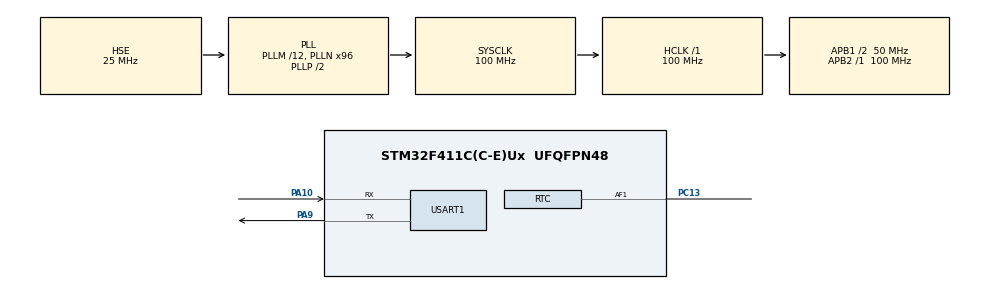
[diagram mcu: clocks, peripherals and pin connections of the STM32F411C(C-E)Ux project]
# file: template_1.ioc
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Dma.Request0=USART1_RX
Dma.Request1=USART1_TX
Dma.USART1_RX.0.Direction=DMA_PERIPH_TO_MEMORY
Dma.USART1_RX.0.FIFOMode=DMA_FIFOMODE_DISABLE
Dma.USART1_RX.0.Instance=DMA2_Stream2
Dma.USART1_RX.0.MemDataAlignment=DMA_MDATAALIGN_BYTE
Dma.USART1_RX.0.MemInc=DMA_MINC_ENABLE
Dma.USART1_RX.0.Mode=DMA_CIRCULAR
Dma.USART1_RX.0.PeriphDataAlignment=DMA_PDATAALIGN_BYTE
Dma.USART1_RX.0.PeriphInc=DMA_PINC_DISABLE
Dma.USART1_RX.0.Priority=DMA_PRIORITY_MEDIUM
Dma.USART1_TX.1.Direction=DMA_MEMORY_TO_PERIPH
Dma.USART1_TX.1.FIFOMode=DMA_FIFOMODE_DISABLE
Dma.USART1_TX.1.Instance=DMA2_Stream7
Dma.USART1_TX.1.MemDataAlignment=DMA_MDATAALIGN_BYTE
Dma.USART1_TX.1.MemInc=DMA_MINC_ENABLE
Dma.USART1_TX.1.Mode=DMA_CIRCULAR
Dma.USART1_TX.1.PeriphDataAlignment=DMA_PDATAALIGN_BYTE
Dma.USART1_TX.1.PeriphInc=DMA_PINC_DISABLE
Dma.USART1_TX.1.Priority=DMA_PRIORITY_MEDIUM
FREERTOS.Queues01=m_input_to_log,1,uint32_t,0,Dynamic,NULL,NULL;m_log_to_output,1,uint32_t,0,Dynamic,NULL,NULL;m_output_to_input,1,uint32_t,0,Dynamic,NULL,NULL
FREERTOS.Tasks01=t_input,32,128,start_t_input,Default,NULL,Dynamic,NULL,NULL;t_log,24,128,start_t_log,Default,NULL,Dynamic,NULL,NULL;t_output,24,128,start_t_output,Default,NULL,Dynamic,NULL,NULL
Mcu.Family=STM32F4
Mcu.Name=STM32F411C(C-E)Ux
Mcu.Package=UFQFPN48
NVIC.DMA2_Stream2_IRQn=true\:7\:0\:true\:false\:true\:true\:false\:true\:true
NVIC.DMA2_Stream7_IRQn=true\:6\:0\:true\:false\:true\:true\:false\:true\:true
NVIC.PriorityGroup=NVIC_PRIORITYGROUP_4
NVIC.TIM1_UP_TIM10_IRQn=true\:15\:0\:false\:false\:true\:false\:false\:true\:true
NVIC.TimeBase=TIM1_UP_TIM10_IRQn
NVIC.TimeBaseIP=TIM10
NVIC.USART1_IRQn=true\:7\:0\:true\:false\:true\:true\:true\:true\:true
PA10.Mode=Asynchronous
PA10.Signal=USART1_RX
PA13.Mode=Serial_Wire
PA13.Signal=SYS_JTMS-SWDIO
PA14.Mode=Serial_Wire
PA14.Signal=SYS_JTCK-SWCLK
PA9.Mode=Asynchronous
PA9.Signal=USART1_TX
PC13-ANTI_TAMP.Mode=WakeUpAF1
PC13-ANTI_TAMP.Signal=RTC_AF1
PC14-OSC32_IN.Mode=LSE-External-Oscillator
PC14-OSC32_IN.Signal=RCC_OSC32_IN
PC15-OSC32_OUT.Mode=LSE-External-Oscillator
PC15-OSC32_OUT.Signal=RCC_OSC32_OUT
PH0\ -\ OSC_IN.Mode=HSE-External-Oscillator
PH0\ -\ OSC_IN.Signal=RCC_OSC_IN
PH1\ -\ OSC_OUT.Mode=HSE-External-Oscillator
PH1\ -\ OSC_OUT.Signal=RCC_OSC_OUT
ProjectManager.HeapSize=0x200
ProjectManager.StackSize=0x400
ProjectManager.TargetToolchain=MDK-ARM V5.32
RCC.48MHZClocksFreq_Value=50000000
RCC.AHBFreq_Value=100000000
RCC.APB1CLKDivider=RCC_HCLK_DIV2
RCC.APB1Freq_Value=50000000
RCC.APB1TimFreq_Value=100000000
RCC.APB2Freq_Value=100000000
RCC.APB2TimFreq_Value=100000000
RCC.CortexFreq_Value=100000000
RCC.HCLKFreq_Value=100000000
RCC.HSE_VALUE=25000000
RCC.HSI_VALUE=16000000
RCC.PLLM=12
RCC.PLLN=96
RCC.PLLSourceVirtual=RCC_PLLSOURCE_HSE
RCC.RCC_RTC_Clock_Source=RCC_RTCCLKSOURCE_LSE
RCC.RCC_RTC_Clock_SourceVirtual=RCC_RTCCLKSOURCE_LSE
RCC.SYSCLKFreq_VALUE=100000000
RCC.SYSCLKSource=RCC_SYSCLKSOURCE_PLLCLK
RCC.VCOOutputFreq_Value=200000000
RTC.Format=RTC_FORMAT_BIN
RTC.OutPutPolarity=RTC_OUTPUT_POLARITY_LOW
RTC.WakeUpClock=RTC_WAKEUPCLOCK_CK_SPRE_16BITS
USART1.VirtualMode=VM_ASYNC
VP_FREERTOS_VS_CMSIS_V2.Mode=CMSIS_V2
VP_RTC_VS_RTC_Activate.Mode=RTC_Enabled
VP_SYS_VS_tim10.Mode=TIM10
board=custom

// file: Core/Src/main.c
/* USER CODE BEGIN Header */
/**
  ******************************************************************************
  * @file           : main.c
  * @brief          : Main program body
  ******************************************************************************
  * @attention
  *
  * Copyright (c) 2024 STMicroelectronics.
  * All rights reserved.
  *
  * This software is licensed under terms that can be found in the LICENSE file
  * in the root directory of this software component.
  * If no LICENSE file comes with this software, it is provided AS-IS.
  *
  ******************************************************************************
  */
/* USER CODE END Header */
#include "main.h"
#include "cmsis_os.h"
#include "dma.h"
#include "rtc.h"
#include "usart.h"
#include "gpio.h"
#include <string.h>

#define APPLICATION_POSADDR ((uint32_t)0x00001000)
#define NVIC_VectTab_FLASH           ((uint32_t)0x08000000)

void NVIC_SetVectorTable(uint32_t NVIC_VectTab, uint32_t Offset)
{
  portDISABLE_INTERRUPTS();
  SCB->VTOR = NVIC_VectTab | (Offset & (uint32_t)0x1FFFFF80);
  portENABLE_INTERRUPTS();
}

void SystemClock_Config(void);
void MX_FREERTOS_Init(void);

int main(void)
{

  /* USER CODE BEGIN 1 */
  NVIC_SetVectorTable(NVIC_VectTab_FLASH, APPLICATION_POSADDR);
  /* USER CODE END 1 */

  /* MCU Configuration--------------------------------------------------------*/

  /* Reset of all peripherals, Initializes the Flash interface and the Systick. */
  HAL_Init();

  /* Configure the system clock */
  SystemClock_Config();

  /* Initialize all configured peripherals */
  MX_GPIO_Init();
  MX_DMA_Init();
  MX_RTC_Init();
  MX_USART1_UART_Init();

  HAL_UART_Transmit_DMA(&huart1, (uint8_t *)"APP\r\n", strlen("APP\r\n"));

  /* Init scheduler */
  osKernelInitialize();

  /* Call init function for freertos objects (in cmsis_os2.c) */
  MX_FREERTOS_Init();

  /* Start scheduler */
  osKernelStart();

  /* We should never get here as control is now taken by the scheduler */

  /* Infinite loop */
  while (1)
  {

  }
}

void SystemClock_Config(void)
{
  RCC_OscInitTypeDef RCC_OscInitStruct = {0};
  RCC_ClkInitTypeDef RCC_ClkInitStruct = {0};

  /** Configure the main internal regulator output voltage
  */
  __HAL_RCC_PWR_CLK_ENABLE();
  __HAL_PWR_VOLTAGESCALING_CONFIG(PWR_REGULATOR_VOLTAGE_SCALE1);

  /** Initializes the RCC Oscillators according to the specified parameters
  * in the RCC_OscInitTypeDef structure.
  */
  RCC_OscInitStruct.OscillatorType = RCC_OSCILLATORTYPE_HSE|RCC_OSCILLATORTYPE_LSE;
  RCC_OscInitStruct.HSEState = RCC_HSE_ON;
  RCC_OscInitStruct.LSEState = RCC_LSE_ON;
  RCC_OscInitStruct.PLL.PLLState = RCC_PLL_ON;
  RCC_OscInitStruct.PLL.PLLSource = RCC_PLLSOURCE_HSE;
  RCC_OscInitStruct.PLL.PLLM = 12;
  RCC_OscInitStruct.PLL.PLLN = 96;
  RCC_OscInitStruct.PLL.PLLP = RCC_PLLP_DIV2;
  RCC_OscInitStruct.PLL.PLLQ = 4;
  if (HAL_RCC_OscConfig(&RCC_OscInitStruct) != HAL_OK)
  {
    Error_Handler();
  }

  /** Initializes the CPU, AHB and APB buses clocks
  */
  RCC_ClkInitStruct.ClockType = RCC_CLOCKTYPE_HCLK|RCC_CLOCKTYPE_SYSCLK
                              |RCC_CLOCKTYPE_PCLK1|RCC_CLOCKTYPE_PCLK2;
  RCC_ClkInitStruct.SYSCLKSource = RCC_SYSCLKSOURCE_PLLCLK;
  RCC_ClkInitStruct.AHBCLKDivider = RCC_SYSCLK_DIV1;
  RCC_ClkInitStruct.APB1CLKDivider = RCC_HCLK_DIV2;
  RCC_ClkInitStruct.APB2CLKDivider = RCC_HCLK_DIV1;

  if (HAL_RCC_ClockConfig(&RCC_ClkInitStruct, FLASH_LATENCY_3) != HAL_OK)
  {
    Error_Handler();
  }
}

void HAL_TIM_PeriodElapsedCallback(TIM_HandleTypeDef *htim)
{
  if (htim->Instance == TIM10) {
    HAL_IncTick();
  }
}

void Error_Handler(void)
{
  __disable_irq();
  while (1)
  {
  }
}

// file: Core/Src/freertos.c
/* USER CODE BEGIN Header */
/**
  ******************************************************************************
  * File Name          : freertos.c
  * Description        : Code for freertos applications
  ******************************************************************************
  * @attention
  *
  * Copyright (c) 2024 STMicroelectronics.
  * All rights reserved.
  *
  * This software is licensed under terms that can be found in the LICENSE file
  * in the root directory of this software component.
  * If no LICENSE file comes with this software, it is provided AS-IS.
  *
  ******************************************************************************
  */
/* USER CODE END Header */

#include "FreeRTOS.h"
#include "task.h"
#include "main.h"
#include "cmsis_os.h"

/* USER CODE BEGIN Includes */
#include "self.h"
/* USER CODE END Includes */

/* Definitions for t_input */
osThreadId_t t_inputHandle;
const osThreadAttr_t t_input_attributes = {
  .name = "t_input",
  .stack_size = 128 * 4,
  .priority = (osPriority_t) osPriorityAboveNormal,
};
/* Definitions for t_log */
osThreadId_t t_logHandle;
const osThreadAttr_t t_log_attributes = {
  .name = "t_log",
  .stack_size = 128 * 4,
  .priority = (osPriority_t) osPriorityNormal,
};
/* Definitions for t_output */
osThreadId_t t_outputHandle;
const osThreadAttr_t t_output_attributes = {
  .name = "t_output",
  .stack_size = 128 * 4,
  .priority = (osPriority_t) osPriorityNormal,
};
/* Definitions for m_input_to_log */
osMessageQueueId_t m_input_to_logHandle;
const osMessageQueueAttr_t m_input_to_log_attributes = {
  .name = "m_input_to_log"
};
/* Definitions for m_log_to_output */
osMessageQueueId_t m_log_to_outputHandle;
const osMessageQueueAttr_t m_log_to_output_attributes = {
  .name = "m_log_to_output"
};
/* Definitions for m_output_to_input */
osMessageQueueId_t m_output_to_inputHandle;
const osMessageQueueAttr_t m_output_to_input_attributes = {
  .name = "m_output_to_input"
};

void start_t_input(void *argument);
void start_t_log(void *argument);
void start_t_output(void *argument);

void MX_FREERTOS_Init(void); /* (MISRA C 2004 rule 8.1) */

void MX_FREERTOS_Init(void) {

  /* Create the queue(s) */
  /* creation of m_input_to_log */
  m_input_to_logHandle = osMessageQueueNew (1, sizeof(uint32_t), &m_input_to_log_attributes);

  /* creation of m_log_to_output */
  m_log_to_outputHandle = osMessageQueueNew (1, sizeof(uint32_t), &m_log_to_output_attributes);

  /* creation of m_output_to_input */
  m_output_to_inputHandle = osMessageQueueNew (1, sizeof(uint32_t), &m_output_to_input_attributes);

  /* Create the thread(s) */
  /* creation of t_input */
  t_inputHandle = osThreadNew(start_t_input, NULL, &t_input_attributes);

  /* creation of t_log */
  t_logHandle = osThreadNew(start_t_log, NULL, &t_log_attributes);

  /* creation of t_output */
  t_outputHandle = osThreadNew(start_t_output, NULL, &t_output_attributes);

}

void start_t_input(void *argument)
{
  /* USER CODE BEGIN start_t_input */
  /* Infinite loop */
  for(;;)
  {
    vTaskDelay(998);
  }
  /* USER CODE END start_t_input */
}

void start_t_log(void *argument)
{
  /* USER CODE BEGIN start_t_log */
  SEGGER_RTT_Init();
  elog_init();

  elog_set_fmt(ELOG_LVL_ASSERT, ELOG_FMT_ALL & ~ELOG_FMT_P_INFO);
  elog_set_fmt(ELOG_LVL_ERROR, ELOG_FMT_LVL | ELOG_FMT_TAG | ELOG_FMT_TIME);
  elog_set_fmt(ELOG_LVL_WARN, ELOG_FMT_LVL | ELOG_FMT_TAG | ELOG_FMT_TIME);
  elog_set_fmt(ELOG_LVL_INFO, ELOG_FMT_LVL | ELOG_FMT_TAG | ELOG_FMT_TIME);
  elog_set_fmt(ELOG_LVL_DEBUG, ELOG_FMT_ALL & ~(ELOG_FMT_FUNC | ELOG_FMT_P_INFO));
  elog_set_fmt(ELOG_LVL_VERBOSE, ELOG_FMT_ALL & ~(ELOG_FMT_FUNC | ELOG_FMT_P_INFO));

  elog_start();

  SEGGER_RTT_printf(0, "Secquence Start. \n");
  /* Infinite loop */
  for(;;)
  {
    log_a("Hello Elog. \n");
    vTaskDelay(200);
    log_d("Hello Elog. \n");
    vTaskDelay(200);
    log_e("Hello Elog. \n");
    vTaskDelay(200);
    log_i("Hello Elog. \n");
    vTaskDelay(200);
    log_v("Hello Elog. \n");
    vTaskDelay(200);
    log_w("Hello Elog. \n");
    vTaskDelay(200);
  }
  /* USER CODE END start_t_log */
}

void start_t_output(void *argument)
{
  /* USER CODE BEGIN start_t_output */
  /* Infinite loop */
  for(;;)
  {
    vTaskDelay(1998);
  }
  /* USER CODE END start_t_output */
}
